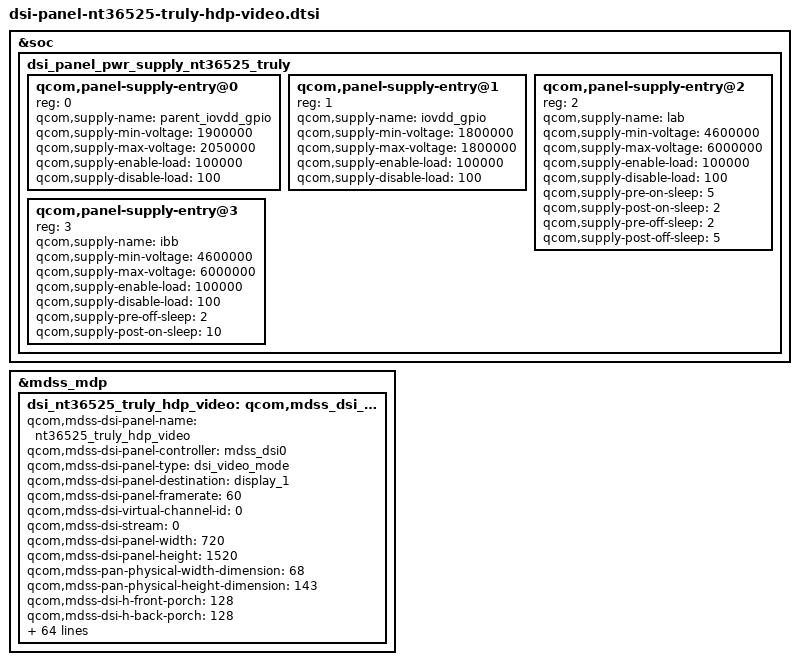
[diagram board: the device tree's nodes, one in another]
/***********************************************************
** Copyright (C), 2008-2016, OPPO Mobile Comm Corp., Ltd.
** ODM_WT_EDIT
** File: - panel_nt36525_truly_hdp_video.h
** Description: source  nt36525 truly panel config in kernel
**
** Version: 1.0
** Date : 2018/05/10
**
** ------------------------------- Revision History: -------------------------------
**  	<author>		<data> 	   <version >	       <desc>
**
****************************************************************/
&soc {
	dsi_panel_pwr_supply_nt36525_truly: dsi_panel_pwr_supply_nt36525_truly {
		#address-cells = <1>;
		#size-cells = <0>;
		qcom,panel-supply-entry@0 {
			reg = <0>;
			qcom,supply-name = "parent_iovdd_gpio";
			qcom,supply-min-voltage = <1900000>;
			qcom,supply-max-voltage = <2050000>;
			qcom,supply-enable-load = <100000>;
			qcom,supply-disable-load = <100>;
		};
		qcom,panel-supply-entry@1 {
			reg = <1>;
			qcom,supply-name = "iovdd_gpio";
			qcom,supply-min-voltage = <1800000>;
			qcom,supply-max-voltage = <1800000>;
			qcom,supply-enable-load = <100000>;
			qcom,supply-disable-load = <100>;
		};
		qcom,panel-supply-entry@2 {
			reg = <2>;
			qcom,supply-name = "lab";
			qcom,supply-min-voltage = <4600000>;
			qcom,supply-max-voltage = <6000000>;
			qcom,supply-enable-load = <100000>;
			qcom,supply-disable-load = <100>;
			qcom,supply-pre-on-sleep = <5>;
			qcom,supply-post-on-sleep = <2>;
			qcom,supply-pre-off-sleep = <2>;
			qcom,supply-post-off-sleep = <5>;
		};
		qcom,panel-supply-entry@3 {
			reg = <3>;
			qcom,supply-name = "ibb";
			qcom,supply-min-voltage = <4600000>;
			qcom,supply-max-voltage = <6000000>;
			qcom,supply-enable-load = <100000>;
			qcom,supply-disable-load = <100>;
			qcom,supply-pre-off-sleep = <2>;
			qcom,supply-post-on-sleep = <10>;
		};
	};
};
&mdss_mdp {
	dsi_nt36525_truly_hdp_video: qcom,mdss_dsi_nt36525_truly_hdp_video {
		qcom,mdss-dsi-panel-name = "nt36525_truly_hdp_video";
		qcom,mdss-dsi-panel-controller = <&mdss_dsi0>;
		qcom,mdss-dsi-panel-type = "dsi_video_mode";
		qcom,mdss-dsi-panel-destination = "display_1";
		qcom,mdss-dsi-panel-framerate = <60>;
		qcom,mdss-dsi-virtual-channel-id = <0>;
		qcom,mdss-dsi-stream = <0>;
		qcom,mdss-dsi-panel-width = <720>;
		qcom,mdss-dsi-panel-height = <1520>;
		qcom,mdss-pan-physical-width-dimension = <68>;
		qcom,mdss-pan-physical-height-dimension = <143>;
		qcom,mdss-dsi-h-front-porch = <128>;
		qcom,mdss-dsi-h-back-porch = <128>;
		qcom,mdss-dsi-h-pulse-width = <2>;
		qcom,mdss-dsi-h-sync-skew = <0>;
		qcom,mdss-dsi-v-back-porch = <4>;
		qcom,mdss-dsi-v-front-porch = <8>;
		qcom,mdss-dsi-v-pulse-width = <2>;
		qcom,mdss-dsi-h-left-border = <0>;
		qcom,mdss-dsi-h-right-border = <0>;
		qcom,mdss-dsi-v-top-border = <0>;
		qcom,mdss-dsi-v-bottom-border = <0>;
		qcom,mdss-dsi-bpp = <24>;
		qcom,mdss-dsi-color-order = "rgb_swap_rgb";
		qcom,mdss-dsi-underflow-color = <0xff>;
		qcom,mdss-dsi-border-color = <0>;
		qcom,mdss-dsi-on-command = [
			29 01 00 00 00 00 02 FF 20
			29 01 00 00 00 00 02 FB 01
			29 01 00 00 00 00 02 05 A9
			29 01 00 00 00 00 02 0E 87
			29 01 00 00 00 00 02 0F 55
			29 01 00 00 00 00 02 1F 00
			29 01 00 00 00 00 02 69 A9
			29 01 00 00 00 00 02 95 D2
			29 01 00 00 00 00 02 96 F5
			29 01 00 00 00 00 02 FF 20
			29 01 00 00 00 00 02 FB 01
			29 01 00 00 00 00 11 B0 00 00 00 2E 00 65 00 8C 00 AA 00 C4 00 DA 00 ED
			29 01 00 00 00 00 11 B1 00 FE 01 36 01 5C 01 99 01 C3 02 03 02 33 02 34
			29 01 00 00 00 00 11 B2 02 64 02 98 02 C0 02 F1 03 10 03 47 03 53 03 64
			29 01 00 00 00 00 0D B3 03 76 03 8C 03 A6 03 C3 03 D9 03 FF
			29 01 00 00 00 00 11 B4 00 00 00 2E 00 65 00 8C 00 AA 00 C4 00 DA 00 ED
			29 01 00 00 00 00 11 B5 00 FE 01 36 01 5C 01 99 01 C3 02 03 02 33 02 34
			29 01 00 00 00 00 11 B6 02 64 02 98 02 C0 02 F1 03 10 03 47 03 53 03 64
			29 01 00 00 00 00 0D B7 03 76 03 8C 03 A6 03 C3 03 D9 03 FF
			29 01 00 00 00 00 11 B8 00 00 00 2E 00 65 00 8C 00 AA 00 C4 00 DA 00 ED
			29 01 00 00 00 00 11 B9 00 FE 01 36 01 5C 01 99 01 C3 02 03 02 33 02 34
			29 01 00 00 00 00 11 BA 02 64 02 98 02 C0 02 F1 03 10 03 47 03 53 03 64
			29 01 00 00 00 00 0D BB 03 76 03 8C 03 A6 03 C3 03 D9 03 FF
			29 01 00 00 00 00 02 FF 21
			29 01 00 00 00 00 02 FB 01
			29 01 00 00 00 00 11 B0 00 00 00 2E 00 65 00 8C 00 AA 00 C4 00 DA 00 ED
			29 01 00 00 00 00 11 B1 00 FE 01 36 01 5C 01 99 01 C3 02 03 02 33 02 34
			29 01 00 00 00 00 11 B2 02 64 02 98 02 C0 02 F1 03 10 03 47 03 53 03 64
			29 01 00 00 00 00 0D B3 03 76 03 8C 03 A6 03 C3 03 D9 03 FF
			29 01 00 00 00 00 11 B4 00 00 00 2E 00 65 00 8C 00 AA 00 C4 00 DA 00 ED
			29 01 00 00 00 00 11 B5 00 FE 01 36 01 5C 01 99 01 C3 02 03 02 33 02 34
			29 01 00 00 00 00 11 B6 02 64 02 98 02 C0 02 F1 03 10 03 47 03 53 03 64
			29 01 00 00 00 00 0D B7 03 76 03 8C 03 A6 03 C3 03 D9 03 FF
			29 01 00 00 00 00 11 B8 00 00 00 2E 00 65 00 8C 00 AA 00 C4 00 DA 00 ED
			29 01 00 00 00 00 11 B9 00 FE 01 36 01 5C 01 99 01 C3 02 03 02 33 02 34
			29 01 00 00 00 00 11 BA 02 64 02 98 02 C0 02 F1 03 10 03 47 03 53 03 64
			29 01 00 00 00 00 0D BB 03 76 03 8C 03 A6 03 C3 03 D9 03 FF
			29 01 00 00 00 00 02 FF 23
			29 01 00 00 00 00 02 FB 01
			29 01 00 00 00 00 02 00 60
			29 01 00 00 00 00 02 07 00
			29 01 00 00 00 00 02 12 AB
			29 01 00 00 00 00 02 15 F5
			29 01 00 00 00 00 02 16 0B
			29 01 00 00 00 00 02 FF 24
			29 01 00 00 00 00 02 FB 01
			29 01 00 00 00 00 02 00 20
			29 01 00 00 00 00 02 01 20
			29 01 00 00 00 00 02 02 05
			29 01 00 00 00 00 02 03 05
			29 01 00 00 00 00 02 04 9F
			29 01 00 00 00 00 02 05 9F
			29 01 00 00 00 00 02 06 9E
			29 01 00 00 00 00 02 07 9E
			29 01 00 00 00 00 02 08 0C
			29 01 00 00 00 00 02 09 03
			29 01 00 00 00 00 02 0A 0D
			29 01 00 00 00 00 02 0B 0E
			29 01 00 00 00 00 02 0C 0F
			29 01 00 00 00 00 02 0D 10
			29 01 00 00 00 00 02 0E 11
			29 01 00 00 00 00 02 0F 12
			29 01 00 00 00 00 02 10 13
			29 01 00 00 00 00 02 11 04
			29 01 00 00 00 00 02 12 04
			29 01 00 00 00 00 02 13 20
			29 01 00 00 00 00 02 14 20
			29 01 00 00 00 00 02 15 20
			29 01 00 00 00 00 02 16 20
			29 01 00 00 00 00 02 17 20
			29 01 00 00 00 00 02 18 05
			29 01 00 00 00 00 02 19 05
			29 01 00 00 00 00 02 1A 9F
			29 01 00 00 00 00 02 1B 9F
			29 01 00 00 00 00 02 1C 9E
			29 01 00 00 00 00 02 1D 9E
			29 01 00 00 00 00 02 1E 0C
			29 01 00 00 00 00 02 1F 03
			29 01 00 00 00 00 02 20 0D
			29 01 00 00 00 00 02 21 0E
			29 01 00 00 00 00 02 22 0F
			29 01 00 00 00 00 02 23 10
			29 01 00 00 00 00 02 24 11
			29 01 00 00 00 00 02 25 12
			29 01 00 00 00 00 02 26 13
			29 01 00 00 00 00 02 27 04
			29 01 00 00 00 00 02 28 04
			29 01 00 00 00 00 02 29 20
			29 01 00 00 00 00 02 2A 20
			29 01 00 00 00 00 02 2B 20
			29 01 00 00 00 00 02 2F 0C
			29 01 00 00 00 00 02 30 40
			29 01 00 00 00 00 02 33 40
			29 01 00 00 00 00 02 34 0C
			29 01 00 00 00 00 02 37 77
			29 01 00 00 00 00 02 3A 9A
			29 01 00 00 00 00 02 3B 95
			29 01 00 00 00 00 02 3D 92
			29 01 00 00 00 00 02 4D 15
			29 01 00 00 00 00 02 4E 26
			29 01 00 00 00 00 02 4F 37
			29 01 00 00 00 00 02 50 48
			29 01 00 00 00 00 02 51 84
			29 01 00 00 00 00 02 52 73
			29 01 00 00 00 00 02 53 62
			29 01 00 00 00 00 02 54 51
			29 01 00 00 00 00 02 55 86
			29 01 00 00 00 00 02 56 78
			29 01 00 00 00 00 02 5A 9A
			29 01 00 00 00 00 02 5B 95
			29 01 00 00 00 00 02 5C 8F
			29 01 00 00 00 00 02 5D 0A
			29 01 00 00 00 00 02 5E 10
			29 01 00 00 00 00 02 60 80
			29 01 00 00 00 00 02 61 7C
			29 01 00 00 00 00 02 64 11
			29 01 00 00 00 00 02 85 11
			29 01 00 00 00 00 02 92 AD
			29 01 00 00 00 00 02 93 08
			29 01 00 00 00 00 02 94 06
			29 01 00 00 00 00 02 AB 00
			29 01 00 00 00 00 02 AD 00
			29 01 00 00 00 00 02 B0 05
			29 01 00 00 00 00 02 B1 A9
			29 01 00 00 00 00 02 FF 25
			29 01 00 00 00 00 02 FB 01
			29 01 00 00 00 00 02 0A 82
			29 01 00 00 00 00 02 0B 9C
			29 01 00 00 00 00 02 0C 01
			29 01 00 00 00 00 02 17 82
			29 01 00 00 00 00 02 18 06
			29 01 00 00 00 00 02 19 0F
			29 01 00 00 00 00 02 1F 9A
			29 01 00 00 00 00 02 20 95
			29 01 00 00 00 00 02 23 05
			29 01 00 00 00 00 02 24 A9
			29 01 00 00 00 00 02 26 9A
			29 01 00 00 00 00 02 27 95
			29 01 00 00 00 00 02 2A 05
			29 01 00 00 00 00 02 2B A9
			29 01 00 00 00 00 02 2F 80
			29 01 00 00 00 00 02 40 10
			29 01 00 00 00 00 02 41 80
			29 01 00 00 00 00 02 42 A6
			29 01 00 00 00 00 02 43 95
			29 01 00 00 00 00 02 46 05
			29 01 00 00 00 00 02 47 A9
			29 01 00 00 00 00 02 4C 95
			29 01 00 00 00 00 02 4E 95
			29 01 00 00 00 00 02 4F A6
			29 01 00 00 00 00 02 50 95
			29 01 00 00 00 00 02 53 05
			29 01 00 00 00 00 02 54 A9
			29 01 00 00 00 00 02 55 05
			29 01 00 00 00 00 02 56 A9
			29 01 00 00 00 00 02 5A 80
			29 01 00 00 00 00 02 5B 80
			29 01 00 00 00 00 02 5D 9A
			29 01 00 00 00 00 02 5E 95
			29 01 00 00 00 00 02 5F 9A
			29 01 00 00 00 00 02 60 95
			29 01 00 00 00 00 02 61 9A
			29 01 00 00 00 00 02 62 95
			29 01 00 00 00 00 02 65 05
			29 01 00 00 00 00 02 66 A9
			29 01 00 00 00 00 02 D5 66
			29 01 00 00 00 00 02 FF 26
			29 01 00 00 00 00 02 FB 01
			29 01 00 00 00 00 02 04 42
			29 01 00 00 00 00 02 06 FF
			29 01 00 00 00 00 02 0C 0B
			29 01 00 00 00 00 02 0D 01
			29 01 00 00 00 00 02 0E 02
			29 01 00 00 00 00 02 0F 06
			29 01 00 00 00 00 02 10 07
			29 01 00 00 00 00 02 13 24
			29 01 00 00 00 00 02 14 88
			29 01 00 00 00 00 02 16 81
			29 01 00 00 00 00 02 19 1A
			29 01 00 00 00 00 02 1A 0D
			29 01 00 00 00 00 02 1B 12
			29 01 00 00 00 00 02 1C 82
			29 01 00 00 00 00 02 1E AD
			29 01 00 00 00 00 02 1F AD
			29 01 00 00 00 00 02 24 00
			29 01 00 00 00 00 02 2F 04
			29 01 00 00 00 00 02 30 AD
			29 01 00 00 00 00 02 31 11
			29 01 00 00 00 00 02 32 11
			29 01 00 00 00 00 02 34 04
			29 01 00 00 00 00 02 35 AD
			29 01 00 00 00 00 02 36 81
			29 01 00 00 00 00 02 37 67
			29 01 00 00 00 00 02 38 11
			29 01 00 00 00 00 02 3F 10
			29 01 00 00 00 00 02 40 AD
			29 01 00 00 00 00 02 58 D6
			29 01 00 00 00 00 02 59 D6
			29 01 00 00 00 00 02 5A D6
			29 01 00 00 00 00 02 5B AD
			29 01 00 00 00 00 02 5C 00
			29 01 00 00 00 00 02 5D 26
			29 01 00 00 00 00 02 5E 10
			29 01 00 00 00 00 02 63 9A
			29 01 00 00 00 00 02 64 95
			29 01 00 00 00 00 02 65 9A
			29 01 00 00 00 00 02 66 95
			29 01 00 00 00 00 02 67 9A
			29 01 00 00 00 00 02 68 95
			29 01 00 00 00 00 02 6B 00
			29 01 00 00 00 00 02 6D 00
			29 01 00 00 00 00 02 70 05
			29 01 00 00 00 00 02 71 D2
			29 01 00 00 00 00 02 73 9A
			29 01 00 00 00 00 02 74 95
			29 01 00 00 00 00 02 77 05
			29 01 00 00 00 00 02 78 D2
			29 01 00 00 00 00 02 7A 9A
			29 01 00 00 00 00 02 7B 95
			29 01 00 00 00 00 02 7E 05
			29 01 00 00 00 00 02 7F D2
			29 01 00 00 00 00 02 82 9A
			29 01 00 00 00 00 02 83 95
			29 01 00 00 00 00 02 84 9A
			29 01 00 00 00 00 02 85 95
			29 01 00 00 00 00 02 86 9A
			29 01 00 00 00 00 02 87 95
			29 01 00 00 00 00 02 8A 05
			29 01 00 00 00 00 02 8B A9
			29 01 00 00 00 00 02 8F 00
			29 01 00 00 00 00 02 90 00
			29 01 00 00 00 00 02 92 05
			29 01 00 00 00 00 02 93 F0
			29 01 00 00 00 00 02 99 0D
			29 01 00 00 00 00 02 9A 36
			29 01 00 00 00 00 02 9B 0C
			29 01 00 00 00 00 02 9C 9E
			29 01 00 00 00 00 02 FF 27
			29 01 00 00 00 00 02 FB 01
			29 01 00 00 00 00 02 13 00
			29 01 00 00 00 00 02 14 55
			29 01 00 00 00 00 02 FF 23
			29 01 00 00 00 00 02 FB 01
			//CABC dimming
			29 01 00 00 00 00 02 05 12
			29 01 00 00 00 00 02 06 03
			//PWM frequency
			29 01 00 00 00 00 02 07 20
			29 01 00 00 00 00 02 08 04
			29 01 00 00 00 00 02 09 00
			//APL
			29 01 00 00 00 00 02 12 AB
			29 01 00 00 00 00 02 15 7B
			29 01 00 00 00 00 02 16 0A
			//UI mode PWM
			29 01 00 00 00 00 02 30 F9
			29 01 00 00 00 00 02 31 F8
			29 01 00 00 00 00 02 32 F6
			29 01 00 00 00 00 02 33 F5
			29 01 00 00 00 00 02 34 F4
			29 01 00 00 00 00 02 35 F3
			29 01 00 00 00 00 02 36 F3
			29 01 00 00 00 00 02 37 F3
			29 01 00 00 00 00 02 38 F2
			29 01 00 00 00 00 02 39 F1
			29 01 00 00 00 00 02 3A ED
			29 01 00 00 00 00 02 3B EB
			29 01 00 00 00 00 02 3D E9
			29 01 00 00 00 00 02 3F E7
			29 01 00 00 00 00 02 40 E6
			29 01 00 00 00 00 02 41 E5
			//Still mode PWM
			29 01 00 00 00 00 02 45 E7
			29 01 00 00 00 00 02 46 E0
			29 01 00 00 00 00 02 47 D6
			29 01 00 00 00 00 02 48 CE
			29 01 00 00 00 00 02 49 CA
			29 01 00 00 00 00 02 4A C6
			29 01 00 00 00 00 02 4B BE
			29 01 00 00 00 00 02 4C BB
			29 01 00 00 00 00 02 4D BB
			29 01 00 00 00 00 02 4E B9
			29 01 00 00 00 00 02 4F B9
			29 01 00 00 00 00 02 50 B9
			29 01 00 00 00 00 02 51 B9
			29 01 00 00 00 00 02 52 B9
			29 01 00 00 00 00 02 53 B9
			29 01 00 00 00 00 02 54 B9
			//moving mode PWM
			29 01 00 00 00 00 02 58 D9
			29 01 00 00 00 00 02 59 D1
			29 01 00 00 00 00 02 5A CA
			29 01 00 00 00 00 02 5B C1
			29 01 00 00 00 00 02 5C BC
			29 01 00 00 00 00 02 5D B6
			29 01 00 00 00 00 02 5E A8
			29 01 00 00 00 00 02 5F 9D
			29 01 00 00 00 00 02 60 9C
			29 01 00 00 00 00 02 61 93
			29 01 00 00 00 00 02 62 8B
			29 01 00 00 00 00 02 63 86
			29 01 00 00 00 00 02 64 7F
			29 01 00 00 00 00 02 65 77
			29 01 00 00 00 00 02 66 6B
			29 01 00 00 00 00 02 67 61

			29 01 00 00 00 00 02 FF 10
			29 01 00 00 00 00 02 FB 01
			29 01 00 00 00 00 02 51 FF
			29 01 00 00 00 00 02 53 2C
			29 01 00 00 00 00 02 FF E0
			29 01 00 00 00 00 02 FB 01
			29 01 00 00 00 00 02 9E 00
			29 01 00 00 00 00 02 FF 10
			29 01 00 00 00 00 02 FB 01
			29 01 00 00 00 00 02 BA 02 // 3 lane
			29 01 00 00 00 00 03 68 06 01
			29 01 00 00 00 00 03 51 00 00
			//29 01 00 00 00 00 02 53 24
			//add cabc default mode ui mode
			29 01 00 00 00 00 02 FF 10
			29 01 00 00 00 00 02 FB 01
			29 01 00 00 00 00 02 53 24
			29 01 00 00 00 00 02 FF 23
			29 01 00 00 00 00 02 FB 01
			29 01 00 00 00 00 02 00 62

			29 01 00 00 00 00 02 FF 10
			29 01 00 00 00 00 02 FB 01
			29 01 00 00 00 00 02 55 01
			05 01 00 00 78 00 02 11 00
			05 01 00 00 20 00 02 29 00];
		qcom,mdss-dsi-off-command = [
			29 01 00 00 00 00 03 51 00 00
			15 01 00 00 00 00 02 FF 10
			15 01 00 00 00 00 02 FB 01
			05 01 00 00 14 00 02 28 00
			05 01 00 00 3C 00 02 10 00];
			//15 01 00 00 00 00 02 4F 01];
		qcom,mdss-dsi-on-command-state = "dsi_lp_mode";
		qcom,mdss-dsi-off-command-state = "dsi_lp_mode";
		qcom,vddio-always-on-enabled;
		qcom,mdss-dsi-h-sync-pulse = <1>;
		qcom,mdss-dsi-traffic-mode = "burst_mode";
		qcom,panel-supply-entries = <&dsi_panel_pwr_supply_nt36525_truly>;
		//qcom,mdss-dsi-lane-map = "lane_map_0123";
		qcom,mdss-dsi-bllp-eof-power-mode;
		qcom,mdss-dsi-bllp-power-mode;
		qcom,mdss-dsi-lane-0-state;
		qcom,mdss-dsi-lane-1-state;
		qcom,mdss-dsi-lane-2-state;
		//qcom,mdss-dsi-lane-3-state;
		//qcom,mdss-dsi-panel-timings = [FB 38 26 00 6A 6C 2C 3C 2F 03 04 00];
		qcom,mdss-dsi-panel-timings-phy-v2 = [21 1D 07 08 04 03 04 A0
		21 1D 07 08 04 03 04 A0
		21 1D 07 08 04 03 04 A0
		21 1D 07 08 04 03 04 A0
		21 16 06 07 04 03 04 A0];
		qcom,mdss-dsi-t-clk-post = <0x0C>;
		qcom,mdss-dsi-t-clk-pre = <0x29>;
		qcom,mdss-dsi-bl-pmic-control-type = "bl_ctrl_dcs";
		qcom,mdss-dsi-bl-min-level = <1>;
		qcom,mdss-dsi-bl-max-level = <2047>;
		qcom,mdss-brightness-max-level = <2047>;
		qcom,blmap-size = <128>;
		qcom,blmap = <
			36 160
			16 223
			17 217
			19 202
			19 200
			20 178
			22 154
			22 147
			24 107
			24 89
			26 45
			27 0
			29 94
			29 95
			30 140
			33 256
			34 304
			36 443
			37 491
			40 654
			40 697
			43 883
			46 1091
			47 1127
			50 1359
			53 1617
			53 1634
			60 2209
			60 2230
			64 2570
			63 2552
			71 3341
			71 3319
			75 3751
			80 4221
			84 4733
			89 5290
			88 5181
			99 6530
			98 6402
			103 7077
			117 8786
			115 8624
			122 9477
			128 10396
			135 11387
			132 11025
			149 13556
			157 14788
			166 16114
			163 15631
			183 19005
			180 18449
			203 22329
			199 21691
			209 23447
			236 28211
			232 27428
			243 29580
			255 31880
			268 34335
			282 36965
			317 44054
			176 15600>;
		qcom,mdss-dsi-dma-trigger = "trigger_sw";
		qcom,mdss-dsi-mdp-trigger = "none";
		qcom,mdss-dsi-lp11-init;
		//qcom,mdss-dsi-init-delay-us = <50000>;
		qcom,mdss-dsi-lp11-deinit;
		qcom,mdss-dsi-reset-sequence = <1 1>, <0 5>, <1 10>;
		qcom,esd-check-enabled;
		qcom,mdss-dsi-panel-status-command = [06 01 00 01 00 00 01 0a];
		qcom,mdss-dsi-panel-status-command-state = "dsi_lp_mode";
		qcom,mdss-dsi-panel-status-read-length = <1>;
		qcom,mdss-dsi-panel-status-value = <0x9C>;
		qcom,mdss-dsi-panel-status-check-mode = "reg_read";
		qcom,mdss-dsi-tx-eot-append;
		//qcom,mdss-dsi-post-init-delay = <1>;

		qcom,mdss-dsi-cabc-off-command = [
		29 01 00 00 00 00 02 FF 10
		29 01 00 00 00 00 02 FB 01
		29 01 00 00 00 00 02 55 00];

		qcom,mdss-dsi-cabc-ui-command = [
		29 01 00 00 00 00 02 FF 10
		29 01 00 00 00 00 02 FB 01
		29 01 00 00 00 00 02 55 01];

		qcom,mdss-dsi-cabc-image-command = [
		29 01 00 00 00 00 02 FF 10
		29 01 00 00 00 00 02 FB 01
		29 01 00 00 00 00 02 55 02];

		qcom,mdss-dsi-cabc-video-command = [
		29 01 00 00 00 00 02 FF 10
		29 01 00 00 00 00 02 FB 01
		29 01 00 00 00 00 02 55 03
		];
	};
};

